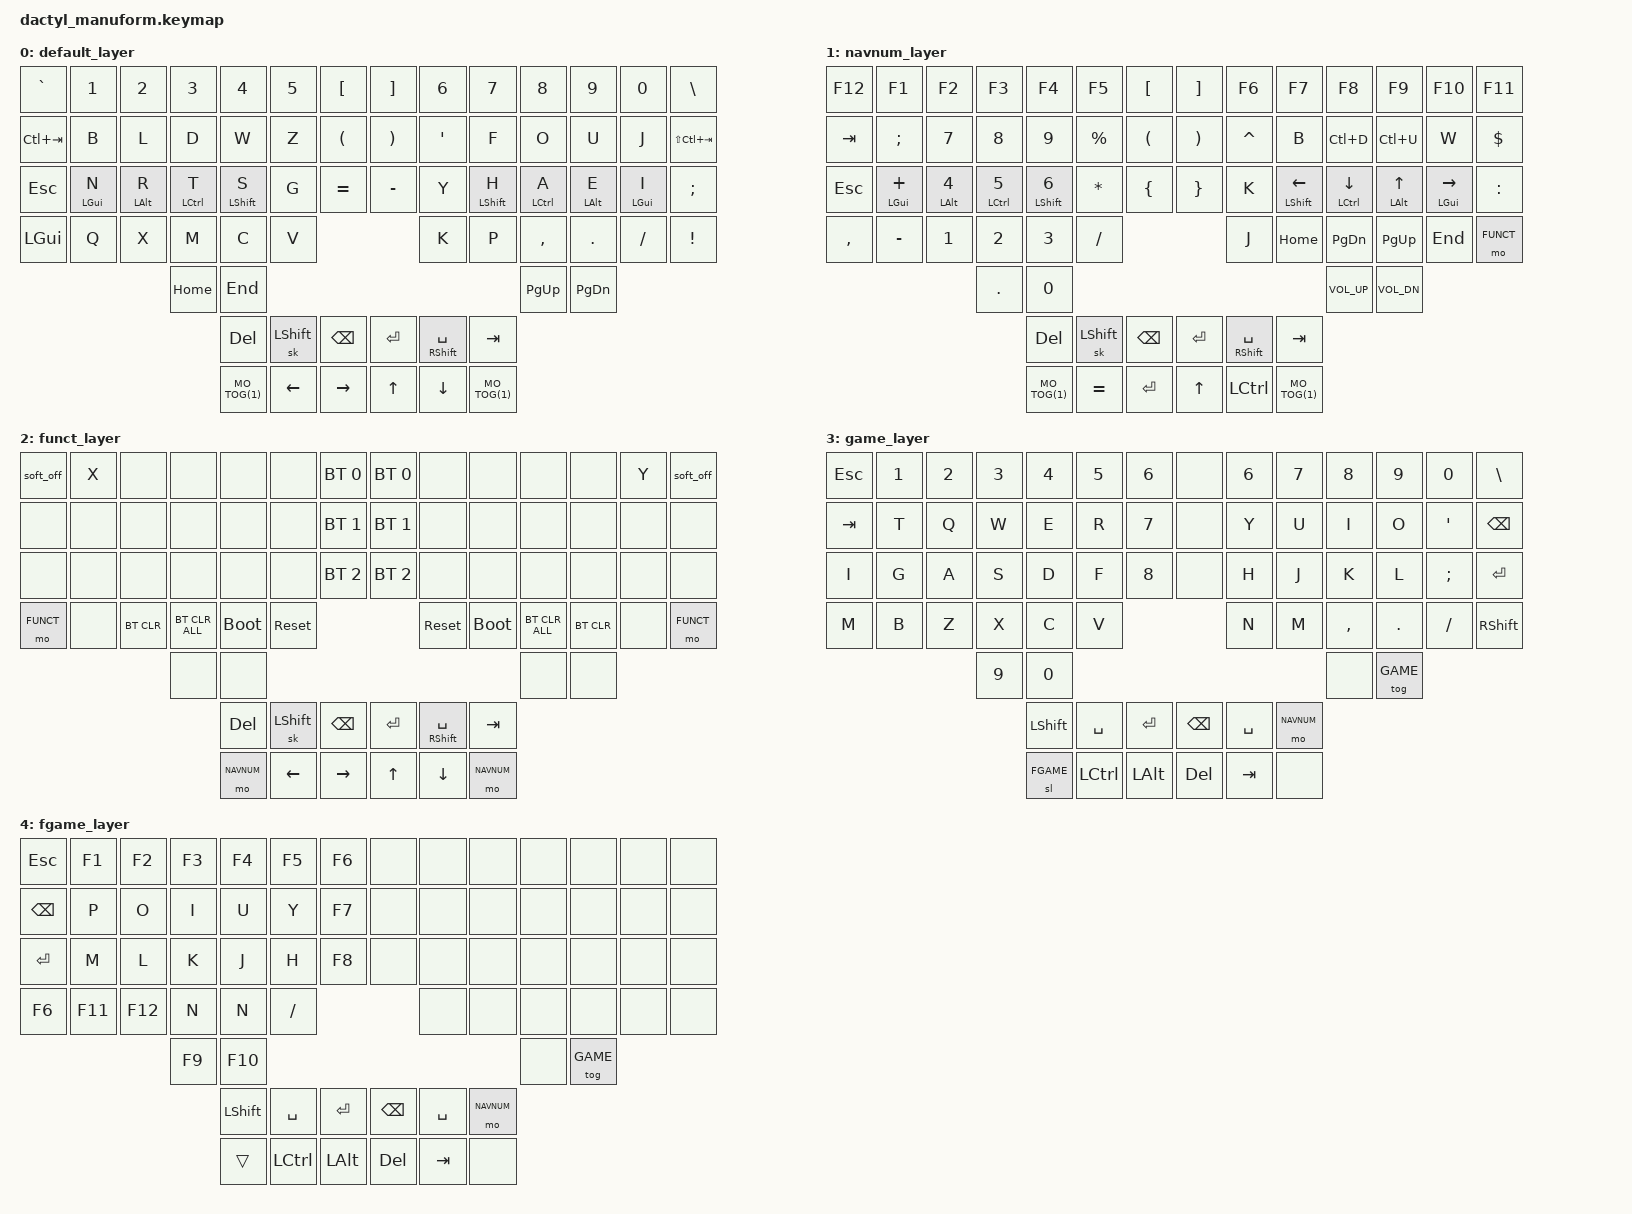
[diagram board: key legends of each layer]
#include <behaviors.dtsi>
#include <dt-bindings/zmk/keys.h>
#include <dt-bindings/zmk/bt.h>
#include <dt-bindings/zmk/outputs.h>
#include <dt-bindings/zmk/mouse.h>

#define DEFAULT 0
#define NAVNUM 1
#define FUNCT 2
#define GAME 3
#define FGAME 4
#define MO_TOG(layer) &mo_tog layer layer   // Macro to apply momentary-layer-on-hold/toggle-layer-on-tap to a specific layer

//this is a test for a 2nd commit in the same push

  // key posiitons 
  // |0  1  2  3  4  5  6  |   |  7  8  9 10 11 12 13 |  
  // |14 15 16 17 18 19 20 |   | 21 22 23 24 25 26 27 |
  // |28 29 30 31 32 33 34 |   | 35 36 37 38 39 40 41 |
  // |42 43 44 45 46 47 |          |48 49 50 51 52 53 |
  //    |54 55 |                         |56 57 |      
  //        |58 59 60|            |61 62 63|
  //        |64 65 66|            |67 68 69|

/ {
  behaviors {

    hml: left_homerow_mods {
      compatible = "zmk,behavior-hold-tap";
      #binding-cells = <2>;
      flavor = "balanced";
      tapping-term-ms = <280>;
      quick-tap-ms = <175>;
      require-prior-idle-ms = <150>;
      bindings = <&kp>, <&kp>;
      hold-trigger-key-positions = <7 8 9 10 11 12 13 21 22 23 24 25 26 27 35 36 37 38 39 40 41 48 49 50 51 52 53 56 57 61 62 63 67 68 69>;
      hold-trigger-on-release;
    };

    hmr: right_homerow_mods {
      compatible = "zmk,behavior-hold-tap";
      #binding-cells = <2>;
      flavor = "balanced";
      tapping-term-ms = <280>;
      quick-tap-ms = <175>;
      require-prior-idle-ms = <150>;
      bindings = <&kp>, <&kp>;
      hold-trigger-key-positions = <0 1 2 3 4 5 6 14 15 16 17 18 19 20 28 29 30 31 32 33 34 42 43 44 45 46 47 54 55 58 59 60 64 65 66>;
      hold-trigger-on-release;
    };

    mo_tog: behavior_mo_tog {
            compatible = "zmk,behavior-hold-tap";
            #binding-cells = <2>;
            flavor = "hold-preferred";
            tapping-term-ms = <200>;
            bindings = <&mo>, <&tog>;
        };
  };

  //combo to trigger GAME layer. 
  combos {
    compatible = "zmk,combos";

    combo_game {
      timeout-ms = <50>;
      key-positions = <54 55>;
      bindings = <&tog GAME>;

    };
    
//Combo to trigger NAVNUM layer
    combo_funct {
      timeout-ms = <50>;
      key-positions = <56 57>;
      bindings = <&tog FUNCT>;
    };
    
//combo to trigger off on left side (turns off both sides)
    combo_softoff1 {
      timeout-ms = <50>;
      key-positions = <0 1>;
      layers = <0>;
      require-prior-idle-ms = <150>;
      bindings = <&soft_off>;
    };
    
//combo to trigger off the right side (turns off both sides)
    combo_softoff2 {
      timeout-ms = <50>;
      key-positions = <12 13>;
      layers = <0>;
      require-prior-idle-ms = <150>;
      bindings = <&soft_off>;
    };
    
//combo to select all on any layer 
    combo_all {
      timeout-ms = <50>;
      key-positions = <44 45 46>;
      bindings = <&kp LC(A)>;
    };
  };


  keymap {
    compatible = "zmk,keymap";

    default_layer {
      bindings = <
        &kp GRAVE    &kp N1    &kp N2       &kp N3        &kp N4         &kp N5 &kp LBKT        &kp RBKT    &kp N6    &kp N7         &kp N8        &kp N9       &kp N0    &kp BSLH 
        &kp LC(TAB)  &kp B     &kp L        &kp D         &kp W          &kp Z  &kp LPAR        &kp RPAR    &kp APOS  &kp F          &kp O         &kp U        &kp J     &kp LS(LC(TAB))
        &kp ESC      &hml LGUI N     &hml LALT R  &hml LCTRL T  &hml LSHIFT S  &kp G  &kp EQUAL       &kp MINUS   &kp Y     &hmr LSHIFT H  &hmr LCTRL A  &hmr LALT E  &hmr LGUI I     &kp SEMI   
        &kp LGUI     &kp Q     &kp X        &kp M         &kp C          &kp V                              &kp K     &kp P          &kp COMMA     &kp DOT      &kp SLASH &kp EXCL
                                        &kp HOME     &kp END                                                                  &kp PG_UP      &kp PG_DN     
                                                            &kp DEL &sk LSHIFT &kp BSPC          &kp ENTER &hmr RSHIFT SPACE &kp TAB
                                                            MO_TOG(1) &kp LEFT  &kp RIGHT       &kp UP  &kp DOWN  MO_TOG(1)
      >;
    };

    navnum_layer {
      bindings = <
        &kp F12      &kp F1         &kp F2       &kp F3        &kp F4         &kp F5      &kp LBKT                          &kp RBKT     &kp F6    &kp F7           &kp F8          &kp F9       &kp F10         &kp F11      
        &kp TAB      &kp SEMI       &kp N7       &kp N8        &kp N9         &kp PERCENT &kp LPAR                          &kp RPAR     &kp CARET &kp B            &kp LC(D)       &kp LC(U)    &kp W           &kp DOLLAR   
        &kp ESC      &hml LGUI PLUS &hml LALT N4 &hml LCTRL N5 &hml LSHIFT N6 &kp STAR    &kp LBRC                          &kp RBRC     &kp K     &hmr LSHIFT LEFT &hmr LCTRL DOWN &hmr LALT UP &hmr LGUI RIGHT &kp COLON     
        &kp COMMA    &kp MINUS      &kp N1       &kp N2        &kp N3         &kp SLASH                                                  &kp J     &kp HOME         &kp PG_DN       &kp PG_UP    &kp END         &mo FUNCT
                                    &kp DOT      &kp N0                                                                                                             &kp C_VOL_UP    &kp C_VOL_DN 
                                                    &kp DEL &sk LSHIFT  &kp BSPC               &kp ENTER   &hmr RSHIFT SPACE  &kp TAB
                                                    MO_TOG(1) &kp EQUAL &kp ENTER              &kp UP  &kp LCTRL MO_TOG(1)
      >;
    };

    funct_layer {
      bindings = <
        &soft_off    &kp X     &none     &none     &none     &none &bt BT_SEL 0            &bt BT_SEL 0 &none     &none     &none     &none     &kp Y     &soft_off    
        &none        &none     &none     &none     &none     &none &bt BT_SEL 1            &bt BT_SEL 1 &none     &none     &none     &none     &none     &none    
        &none        &none     &none     &none     &none     &none &bt BT_SEL 2            &bt BT_SEL 2 &none     &none     &none     &none     &none     &none
        &mo FUNCT    &none     &bt BT_CLR &bt BT_CLR_ALL     &bootloader &sys_reset       &sys_reset &bootloader &bt BT_CLR_ALL &bt BT_CLR     &none     &mo FUNCT        
                                                &none     &none                                                   &none     &none     
                                            &kp DEL &sk LSHIFT &kp BSPC                       &kp ENTER   &hmr RSHIFT SPACE  &kp TAB
                                          &mo NAVNUM &kp LEFT  &kp RIGHT                    &kp UP  &kp DOWN  &mo NAVNUM
      >;
    };

    game_layer {
      bindings = <
        &kp ESC      &kp N1    &kp N2    &kp N3    &kp N4    &kp N5  &kp N6       &none     &kp N6    &kp N7    &kp N8    &kp N9    &kp N0    &kp BSLH     
        &kp TAB      &kp T     &kp Q     &kp W     &kp E     &kp R   &kp N7       &none     &kp Y     &kp U     &kp I     &kp O     &kp APOS  &kp BSPC
        &kp I        &kp G     &kp A     &kp S     &kp D     &kp F   &kp N8       &none     &kp H     &kp J     &kp K     &kp L     &kp SEMI     &kp ENTER   
        &kp M        &kp B     &kp Z     &kp X     &kp C     &kp V                        &kp N     &kp M     &kp COMMA &kp DOT   &kp SLASH &kp RSHIFT     
                                        &kp N9    &kp N0                                                                       &none     &tog GAME     
                                          &kp LSHIFT &kp SPACE &kp ENTER                &kp BSPC  &kp SPACE  &mo NAVNUM
                                          &sl FGAME  &kp LCTRL  &kp LALT                      &kp DEL   &kp TAB &none       
      >;
    };

    fgame_layer {
      bindings = <
        &kp ESC    &kp F1    &kp F2    &kp F3    &kp F4    &kp F5 &kp F6       &none   &none     &none     &none     &none     &none     &none      
        &kp BSPC   &kp P     &kp O     &kp I     &kp U     &kp Y  &kp F7       &none   &none     &none     &none     &none     &none     &none      
        &kp ENTER  &kp M     &kp L     &kp K     &kp J     &kp H  &kp F8       &none   &none     &none     &none     &none     &none     &none      
        &kp F6     &kp F11   &kp F12   &kp N     &kp N     &kp SLASH                   &none     &none     &none     &none     &none     &none                                      
                                      &kp F9     &kp F10                                                                       &none     &tog GAME     
                                        &kp LSHIFT &kp SPACE &kp ENTER                &kp BSPC  &kp SPACE  &mo NAVNUM
                                        &trans     &kp LCTRL  &kp LALT                      &kp DEL   &kp TAB &none       
      >;
    };
  };
};
